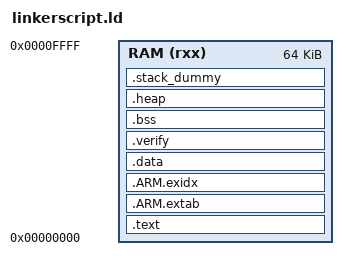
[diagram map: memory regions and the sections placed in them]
/*********************************************************
 *                                                       *
 *  EE511 Project 1                                      *
 *                                                       *
 *  Linker Script for Test Codes                         *
 *                                                       *
 *********************************************************/

MEMORY
{
  RAM (rxx) : ORIGIN = 0x0, LENGTH = 0x10000 /* 64K */
}

ENTRY(Reset_Handler)

SECTIONS
{
	.text :
	{
		KEEP(*(.isr_vector))
    *(.startup*)
		*(.text*)

		KEEP(*(.init))
		KEEP(*(.fini))

		/* .ctors */
		*crtbegin.o(.ctors)
		*crtbegin?.o(.ctors)
		*(EXCLUDE_FILE(*crtend?.o *crtend.o) .ctors)
		*(SORT(.ctors.*))
		*(.ctors)

		/* .dtors */
 		*crtbegin.o(.dtors)
 		*crtbegin?.o(.dtors)
 		*(EXCLUDE_FILE(*crtend?.o *crtend.o) .dtors)
 		*(SORT(.dtors.*))
 		*(.dtors)

		*(.rodata*)

		KEEP(*(.eh_frame*))
	} > RAM

	.ARM.extab :
	{
		*(.ARM.extab* .gnu.linkonce.armextab.*)
	} > RAM

	__exidx_start = .;
	.ARM.exidx :
	{
		*(.ARM.exidx* .gnu.linkonce.armexidx.*)
	} > RAM
	__exidx_end = .;

	__etext = .;

	.data : AT (__etext)
	{
		__data_start__ = .;
		*(vtable)
		*(.data*)

		. = ALIGN(4);
		/* preinit data */
		PROVIDE_HIDDEN (__preinit_array_start = .);
		KEEP(*(.preinit_array))
		PROVIDE_HIDDEN (__preinit_array_end = .);

		. = ALIGN(4);
		/* init data */
		PROVIDE_HIDDEN (__init_array_start = .);
		KEEP(*(SORT(.init_array.*)))
		KEEP(*(.init_array))
		PROVIDE_HIDDEN (__init_array_end = .);

		. = ALIGN(4);
		/* finit data */
		PROVIDE_HIDDEN (__fini_array_start = .);
		KEEP(*(SORT(.fini_array.*)))
		KEEP(*(.fini_array))
		PROVIDE_HIDDEN (__fini_array_end = .);

		KEEP(*(.jcr*))
		. = ALIGN(4);
		/* All data end */
		__data_end__ = .;

	} > RAM

  .verify :
  {
    *(.VERIFY*)
  } > RAM

	.bss :
	{
		. = ALIGN(4);
		__bss_start__ = .;
		*(.bss*)
		*(COMMON)
		. = ALIGN(4);
		__bss_end__ = .;
	} > RAM

	.heap (COPY):
	{
		__end__ = .;
		end = __end__;
		*(.heap*)
		__HeapLimit = .;
	} > RAM

	.stack_dummy (COPY):
	{
		*(.stack*)
	} > RAM

	__StackTop = ORIGIN(RAM) + LENGTH(RAM);
	__StackLimit = __StackTop - SIZEOF(.stack_dummy);
	PROVIDE(__stack = __StackTop);

	ASSERT(__StackLimit >= __HeapLimit, "region RAM overflowed with stack")
}
